# ADuCM410 register map
Vendor: Analog Devices; Series: ADuCM410; File version: 1p0
CPU: CM33 r0p1, little endian, MPU, FPU, 3 interrupt priority bits
Registers are 32-bit, read-write, reset 0x0 unless marked. A register's access mark holds for its fields unless they carry their own. Offsets are from the block's base; [hi:lo] are bit positions; 'fields as' and 'values as' point back to an identical list.

## FLASH
Base 0x40048000
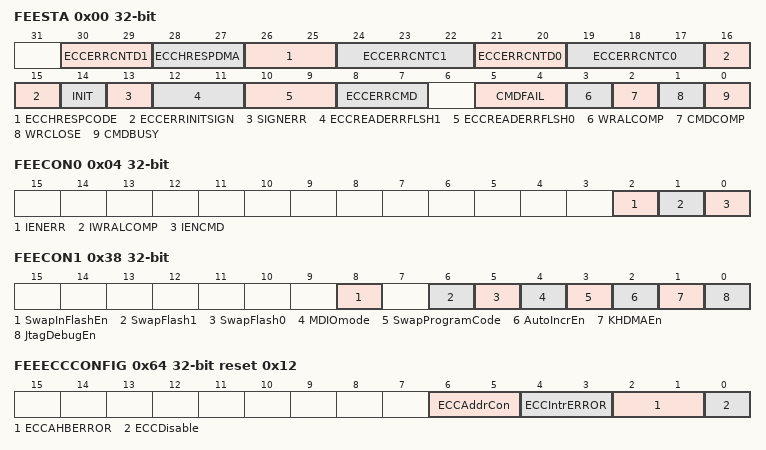
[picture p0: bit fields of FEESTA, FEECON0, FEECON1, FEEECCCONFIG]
0x00 FEESTA — Status Register
  [30:29] ECCERRCNTD1 ro — ECC Error Count via DMA Bus of Flash 1
  [28:27] ECCHRESPDMA ro — ECC Error Response on DMA Bus
    0=No Error. Successful Read from Program Flash via AHB Bus; 1=Error2bit (During AHB Read to Flash, 2 Bit Error Detected, Not Corrected.); 2=Error1bit (1 Bit Error is Corrected for One Flash Location While Doing AHB Read to Program Flash)
  [26:25] ECCHRESPCODE ro — ECC Error Response on CODE Bus
    values as ECCHRESPDMA
  [24:22] ECCERRCNTC1 ro — ECC Error Count via CODE Bus of Flash 1
  [21:20] ECCERRCNTD0 ro — ECC Error Count via DMA Bus of Flash 0
  [19:17] ECCERRCNTC0 ro — ECC Error Count via CODE Bus of Flash 0
  [16:15] ECCERRINITSIGN ro — ECC Error on Initial Info Signature Check
    0=No Error, Successful Flash Read Operation During Initial Signature Check, Page Signature Check; 1=Error2bit (During Initial Signature Check, 2 Bit Error Detected, Not Corrected for at Least One Flash Location); 2=Error1bit (1 Bit Error is Corrected for One Flash Location While Doing Signature Commands); 3=Error1or2bit (During Initial Signature Command, 1 Bit Error and 2 Bit Errors are Detected on One or More Flash Locations)
  [14] INIT ro — Initialization Upload in Progress.
  [13] SIGNERR ro — Initial Signature Check Error on Info Space
  [12:11] ECCREADERRFLSH1 ro — ECC Interrupt Errors During AHB Read to Flash 1.
    0=No Error. Successful Read from Data Flash via AHB Bus; 1=Error2bit (1 Bit Error is Corrected for One Flash Location While Doing AHB Read to Data Flash); 2=Error1bit (During AHB Read to Flash, 2 Bit Error Detected, Not Corrected.); 3=Error1or2bit (During AHB Read, It is Either ECC Error or ECC Corrected Error Only. but This Condition Can Occur If the Consecutive Access Had AHB HRESP Error Due to ECC Error, Before the Status Register is Read.)
  [10:9] ECCREADERRFLSH0 ro — ECC Interrupt Errors During AHB Read to Flash 0.
    0=No Error. Successful Read from Program Flash via AHB Bus; 1=Error2bit (During AHB Read to Flash, 2 Bit Error Detected, Not Corrected.); 2=Error1bit (1 Bit Error is Corrected for One Flash Location While Doing AHB Read to Program Flash); 3=Error1or2bit (During AHB Read, It is Either ECC Error or ECC Corrected Error Only. but This Condition Can Occur If the Consecutive Access Had AHB HRESP Error Due to ECC Error, Before the Status Register is Read.)
  [8:7] ECCERRCMD ro — ECC Errors Produced During Signature Commands
    0=No Error, Successful Flash Read Operation During Signature Check; 1=Error2bit (During Signature Commands, 2 Bit Error is Detected on One or More Flash Locations, Not Corrected.); 2=Error1bit (1 Bit Error is Corrected for One or More Flash Locations While Doing Signature Commands); 3=Error1or2bit (During Signature Commands, 1 Bit Error and 2 Bit Errors are Detected on One or More Flash Locations)
  [5:4] CMDFAIL ro — Command Failed
    0=SUCCESS (Successful Completion of a Command or a Write); 1=DENIED (Attempted Signcheck,write or Erase of a Protected Location or Out of Memory Location. the Command is Ignored.); 2=VERIFYERR (Read Verify Error); 3=ABORTED (Indicates That a Command or a Write Was Aborted by an Abort Command or a System Interrupt Has Caused an Abort)
  [3] WRALCOMP ro — Write Almost Complete - Key-hole Registers Open for Access
  [2] CMDCOMP ro — Command Complete
  [1] WRCLOSE ro — Key-hole Registers Closed for Access
  [0] CMDBUSY ro — Command Busy.
0x04 FEECON0 — Command Control Register - Interrupt Enable Register
  [2] IENERR range 0x00000000..0x00000001 — Command Fail Interrupt Enable
  [1] IWRALCOMP range 0x00000000..0x00000001 — Write Almost Complete Interrupt Enable
  [0] IENCMD range 0x00000000..0x00000001 — Command Complete Interrupt Enable
0x08 FEECMD — Command Register
  [4:0] CMD — Commands
    0=IDLE; 1=ERASEPAGE; 2=SIGN; 4=WRITE; 5=MASSERASE_ACTIVE; 6=MASSERASE_PASSIVE; 8=ABORT
0x0C FEEFLADR — Flash Address Key - Hole Register
  [20:3] FLAddr range 0x00000000..0x0003FFFF — Memory Mapped Address for the Flash Location
0x10 FEEFLDATA0 — Flash Data Register - Key - Hole Interface Lower 32 Bits
  [31:0] FLData0 range 0x00000000..0xFFFFFFFF — Lower 32 Bit of 64 Bit Data to Be Written to Flash
0x14 FEEFLDATA1 — Flash Data Register - Key - Hole Interface Upper 32 Bits
  [31:0] FLData1 range 0x00000000..0xFFFFFFFF — Upper 32 Bit of 64 Bit Data to Be Written to Flash
0x18 FEEADR0 — Lower Page Address
  [20:13] PageAddr0 range 0x00000000..0x000000FF — Page Address 0
0x1C FEEADR1 — Upper Page Address
  [20:13] PageAddr1 range 0x00000000..0x000000FF — Page Address 1
0x20 FEEKEY — Flash Key Register.
  [31:0] KEY wo range 0x00000000..0xFFFFFFFF
0x28 FEEPRO0 reset 0xFFFFFFFF — Write Protection Register for Flash0
  [31:0] WrProt0 range 0x00000000..0xFFFFFFFF — Write Protection for Flash0 - 32 Bits.
0x2C FEEPRO1 reset 0xFFFFFFFF — Write Protection Register for Flash1
  [31:0] WrProt1 range 0x00000000..0xFFFFFFFF — Write Protection for Flash1 - 32 Bits.
0x34 FEESIG — Flash Signature
  [23:0] Sign ro — Signature
0x38 FEECON1 — User Setup Register
  [8] SwapInFlashEn ro — Swap Inside Flash Enable
  [6] SwapFlash1 range 0x00000000..0x00000001 — Swap Top and Bottom Image Inside Flash 1.
  [5] SwapFlash0 range 0x00000000..0x00000001 — Swap Top and Bottom Image Inside Flash 0.
  [4] MDIOmode ro
  [3] SwapProgramCode range 0x00000000..0x00000001 — Swap Program Code for MDIO Mode.
  [2] AutoIncrEn range 0x00000000..0x00000001 — Auto Address Increment for Key Hole Access.
  [1] KHDMAEn range 0x00000000..0x00000001 — Key - Hole DMA Enable.
  [0] JtagDebugEn range 0x00000000..0x00000001 — JTAG Debug Enable
0x40 FEEWRADDRA — Write Abort Address Register
  [31:0] WrAbortAddr ro — Write Abort Address
0x48 FEEAEN0 — Lower 32 Bits of the Sys Irq Abort Enable Register.
  [31:0] SysIrqAbortEn range 0x00000000..0xFFFFFFFF — Lower 32 Bits of System Interrupt Abort Enable.
0x4C FEEAEN1 — Middle 32 Bits of the Sys Irq Abort Enable Register.
  [31:0] SysIrqAbortEn range 0x00000000..0xFFFFFFFF — Middle 32 Bits of System Interrupt Abort Enable.
0x50 FEEAEN2 — Upper 32 Bits of the Sys Irq Abort Enable Register.
  [31:0] SysIrqAbortEn range 0x00000000..0xFFFFFFFF — Upper 32 Bits of System Interrupt Abort Enable.
0x64 FEEECCCONFIG reset 0x12 — Configurable ECC Enable/disable, Error Response
  [6:5] ECCAddrCon — ECC Error Address Control Bit.
    0=NBufNClr (ECC Error Address Register Can't Be Cleared Until Reset; Current ECC Error Address Will Be Returned Directly When Reading ECC_ADDR MMR.); 1=BufNClr (ECC Error Address Register Can't Be Cleared Until Reset; ECC Error Address is Latched on Read of STATUS MMR, and It Will Be Returned When Reading ECC_ADDR MMR.); 2=BufClr2 (Previous ECC Error Address Register is Cleared on Read of STATUS MMR; ECC Error Address is Latched on Read of STATUS MMR, and It Will Be Returned When Reading ECC_ADDR MMR.); 3=BufClr3 (Previous ECC Error Address Register is Cleared on Read of STATUS MMR; ECC Error Address is Latched on Read of STATUS MMR, and It Will Be Returned When Reading ECC_ADDR MMR.)
  [4:3] ECCIntrERROR — Interrupt Enable When a ECC Error Happens During an AHB Read
    0=Disable (Interrupt is Not Generated Even If There is an ECC Error While Reading from Flash via AHB. This Applies to Both Flash.); 1=Error2bitEn (Interrupt is Generated Only If 2 Bit Error is Detected During AHB Read to Flash 0 or 1.); 2=Error1bitEn (Interrupt is Generated Only If 1 Bit Error Corrected During AHB Read to Flash 0 or 1.); 3=Error1or2bitEn (Interrupt is Generated If Either 2 Bit Detected or 1 Bit Error Corrected During AHB Read to Flash 0 or 1.)
  [2:1] ECCAHBERROR — Signifies How to Generate AHB Error on ECC
    0=NoError (AHB Error (HRESP = 1) is Not Generated Even If There is an ECC Error While Reading from Flash via AHB. This Applies to Both Flash.); 1=Error2bit (AHB Error (HRESP = 1) is Generated Only If 2 Bit Error is Detected During AHB Read to Flash 0 or 1.); 2=Error1bit (AHB Error (HRESP = 1) is Generated Only If 1 Bit Error Corrected During AHB Read to Flash 0 or 1); 3=Error1or2bit (AHB Error (HRESP = 1) is Generated If Either 2 Bit Detected or 1 Bit Error Corrected During AHB Read to Flash 0 or 1)
  [0] ECCDisable range 0x00000000..0x00000001 — ECC Disable Bit.
0x74 FEEECCADDRC0 — Flash 0 ECC Error Address via CODE Bus
  [20:0] FLECCAddrC0 ro — Flash0 Address for Which ECC Error is Detected via CODE Bus.
0x78 FEEECCADDRC1 — Flash 1 ECC Error Address via CODE Bus
  [20:0] FLECCAddrC1 ro — Flash1 Address for Which ECC Error is Detected via CODE Bus.
0x94 FEEECCADDRD0 — Flash 0 ECC Error Address via DMA Bus
  [20:0] FLECCAddrD0 ro — Flash0 Address for Which ECC Error is Detected via DMA Bus.
0x98 FEEECCADDRD1 — Flash 1 ECC Error Address via DMA Bus
  [20:0] FLECCAddrD1 ro — Flash1 Address for Which ECC Error is Detected via DMA Bus.
